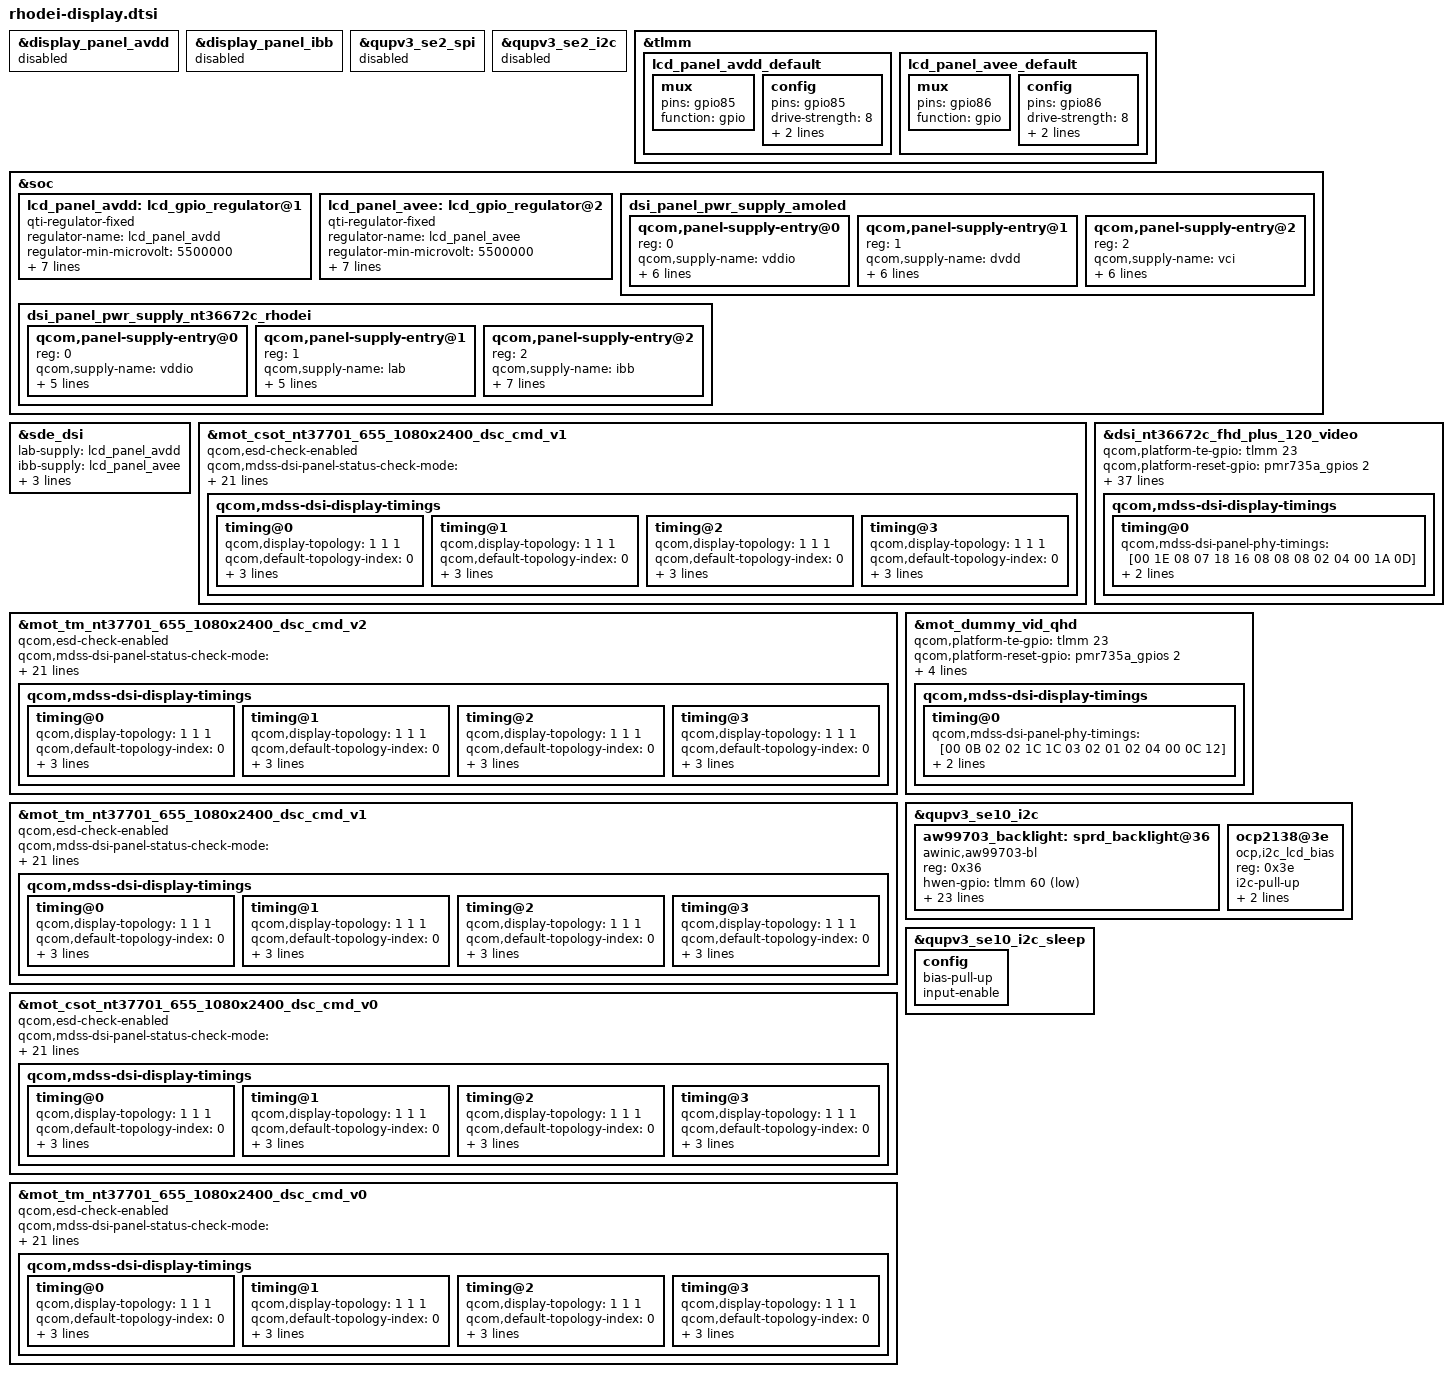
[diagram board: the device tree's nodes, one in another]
#include "dsi-panel-mot-csot-nt37701-655-1080x2400-dsc-cmd-common.dtsi"
#include "dsi-panel-mot-csot-nt37701-655-1080x2400-dsc-cmd-common-v1.dtsi"
#include "dsi-panel-mot-tianma-nt37701-655-1080x2400-dsc-cmd-common.dtsi"
#include "dsi-panel-mot-tianma-nt37701-655-1080x2400-dsc-cmd-common-v1.dtsi"
#include "dsi-panel-mot-tianma-nt37701-655-1080x2400-dsc-cmd-common-v2.dtsi"
#include "dsi-panel-mot-dummy-qhd-video.dtsi"
#include "dsi-panel-mot-tianma-nt36672c-645-1080x2400-video.dtsi"

&display_panel_avdd {
	/delete-property/ gpio;
	/delete-property/ pinctrl-0;
};

&display_panel_avdd {
	status = "disabled";
};

&display_panel_ibb {
	status = "disabled";
};

&qupv3_se2_spi {
	status = "disabled";
};

&qupv3_se2_i2c {
	status = "disabled";
};

&tlmm {
	lcd_panel_avdd_default: lcd_panel_avdd_default {
		mux {
			pins = "gpio85";
			function = "gpio";
		};

		config {
			pins = "gpio85";
			drive-strength = <8>;
			bias-disable = <0>;
			output-high;
		};
	};

	lcd_panel_avee_default: lcd_panel_avee_default {
		mux {
			pins = "gpio86";
			function = "gpio";
		};

		config {
			pins = "gpio86";
			drive-strength = <8>;
			bias-disable = <0>;
			output-high;
		};
	};
};

&soc {
	lcd_panel_avdd: lcd_gpio_regulator@1 {
		compatible = "qti-regulator-fixed";
		regulator-name = "lcd_panel_avdd";
		regulator-min-microvolt = <5500000>;
		regulator-max-microvolt = <5500000>;
		regulator-enable-ramp-delay = <233>;
		gpio = <&tlmm 85 0>;
		enable-active-high;
		regulator-boot-on;
		proxy-supply = <&lcd_panel_avdd>;
		pinctrl-names = "default";
		pinctrl-0 = <&lcd_panel_avdd_default>;
	};

	lcd_panel_avee: lcd_gpio_regulator@2 {
		compatible = "qti-regulator-fixed";
		regulator-name = "lcd_panel_avee";
		regulator-min-microvolt = <5500000>;
		regulator-max-microvolt = <5500000>;
		regulator-enable-ramp-delay = <233>;
		gpio = <&tlmm 86 0>;
		enable-active-high;
		regulator-boot-on;
		proxy-supply = <&lcd_panel_avee>;
		pinctrl-names = "default";
		pinctrl-0 = <&lcd_panel_avee_default>;
	};

	dsi_panel_pwr_supply_amoled: dsi_panel_pwr_supply_amoled {
		#address-cells = <1>;
		#size-cells = <0>;

		qcom,panel-supply-entry@0 {
			reg = <0>;
			qcom,supply-name = "vddio";
			qcom,supply-min-voltage = <1800000>;
			qcom,supply-max-voltage = <1800000>;
			qcom,supply-enable-load = <60700>;
			qcom,supply-disable-load = <80>;
		        qcom,supply-post-on-sleep = <2>;
			qcom,supply-post-off-sleep = <0>;
		};

		qcom,panel-supply-entry@1 {
			reg = <1>;
			qcom,supply-name = "dvdd";
			qcom,supply-min-voltage = <1250000>;
			qcom,supply-max-voltage = <1250000>;
			qcom,supply-enable-load = <60700>;
			qcom,supply-disable-load = <10>;
		        qcom,supply-post-on-sleep = <2>;
		        qcom,supply-post-off-sleep = <2>;
		};

		qcom,panel-supply-entry@2 {
			reg = <2>;
			qcom,supply-name = "vci";
			qcom,supply-min-voltage = <3000000>;
			qcom,supply-max-voltage = <3000000>;
			qcom,supply-enable-load = <30000>;
			qcom,supply-disable-load = <0>;
			qcom,supply-post-on-sleep = <0>;
			qcom,supply-post-off-sleep = <2>;
		};
	};

	dsi_panel_pwr_supply_nt36672c_rhodei: dsi_panel_pwr_supply_nt36672c_rhodei{
		#address-cells = <1>;
		#size-cells = <0>;

		qcom,panel-supply-entry@0 {
			reg = <0>;
			qcom,supply-name = "vddio";
			qcom,supply-min-voltage = <1800000>;
			qcom,supply-max-voltage = <1904000>;
			qcom,supply-enable-load = <32000>;
			qcom,supply-disable-load = <80>;
			qcom,supply-pre-off-sleep = <150>;
		};

		qcom,panel-supply-entry@1 {
			reg = <1>;
			qcom,supply-name = "lab";
			qcom,supply-min-voltage = <5500000>;
			qcom,supply-max-voltage = <5500000>;
			qcom,supply-enable-load = <100000>;
			qcom,supply-disable-load = <100>;
			qcom,supply-pre-on-sleep = <3>;
		};

		qcom,panel-supply-entry@2 {
			reg = <2>;
			qcom,supply-name = "ibb";
			qcom,supply-min-voltage = <5500000>;
			qcom,supply-max-voltage = <5500000>;
			qcom,supply-enable-load = <100000>;
			qcom,supply-disable-load = <100>;
			qcom,supply-pre-off-sleep = <3>;
			qcom,supply-post-on-sleep = <3>;
			qcom,supply-post-off-sleep = <5>;
		};

	};
};

&sde_dsi {
	/delete-property/ lab-supply;
	/delete-property/ ibb-supply;
	/delete-property/ vddio-supply;
	/delete-property/ qcom,dsi-default-panel;
	/delete-property/ avdd-supply;

	lab-supply = <&lcd_panel_avdd>;
	ibb-supply = <&lcd_panel_avee>;
	vddio-supply = <&L13A>;

	qcom,dsi-default-panel = <&dsi_nt36672c_fhd_plus_120_video>;
};

&mot_csot_nt37701_655_1080x2400_dsc_cmd_v1 {
	qcom,esd-check-enabled;
	qcom,mdss-dsi-panel-status-check-mode = "te_chk_reg_rd";
	qcom,mdss-dsi-panel-status-command = [06 01 00 01 00 00 01 0a];
	qcom,mdss-dsi-panel-status-command-state = "dsi_lp_mode";
	qcom,mdss-dsi-panel-status-value = <0x9c>;
	qcom,mdss-dsi-panel-status-read-length = <1>;

	qcom,panel-supply-entries = <&dsi_panel_pwr_supply_amoled>;
	qcom,mdss-dsi-no-panel-on-read-support;
	qcom,mdss-dsi-bl-pmic-control-type = "bl_ctrl_dcs";
	qcom,mdss-dsi-bl-min-level = <9>;
	qcom,mdss-dsi-bl-max-level = <3514>;
	qcom,mdss-dsi-bl-default-level = <1757>;
	qcom,mdss-brightness-max-level = <3514>;
	qcom,platform-te-gpio = <&tlmm 23 0>;
	qcom,platform-reset-gpio = <&pmr735a_gpios 2 0>;
	qcom,bl-dsc-cmd-state = "dsi_hs_mode";

	/*qcom,mdss-dsi-panel-hdr-enabled;
	qcom,mdss-dsi-panel-hdr-color-primaries = <14950 15750 34000
	        16000 13000 35500 7000 2500>;
	qcom,mdss-dsi-panel-peak-brightness = <5000000>;
	qcom,mdss-dsi-panel-blackness-level = <100>;*/

	qcom,dsi-select-clocks = "mux_byte_clk0", "mux_pixel_clk0";

	qcom,mdss-dsi-display-timings {
		timing@0 {
			//qcom,mdss-dsi-panel-clockrate = <320000000>;
			qcom,display-topology = <1 1 1>;
			qcom,default-topology-index = <0>;
			qcom,mdss-dsi-panel-phy-drive-strength = <255>;
			qcom,mdss-dsi-panel-phy-timings = [00 0D 03 03 10 1D 04
							03 02 02 04 00 0C 08];
		};
		timing@1 {
			//qcom,mdss-dsi-panel-clockrate = <400000000>;
			qcom,display-topology = <1 1 1>;
			qcom,default-topology-index = <0>;
			qcom,mdss-dsi-panel-phy-drive-strength = <255>;
			qcom,mdss-dsi-panel-phy-timings = [00 10 03 03 11 1E 04
							04 03 02 04 00 0E 08];
		};
		timing@2 {
			//qcom,mdss-dsi-panel-clockrate = <601000000>;
			qcom,display-topology = <1 1 1>;
			qcom,default-topology-index = <0>;
			qcom,mdss-dsi-panel-phy-drive-strength = <255>;
			qcom,mdss-dsi-panel-phy-timings = [00 16 05 05 14 1F 06
							06 06 02 04 00 13 0A];
		};
		timing@3 {
			//qcom,mdss-dsi-panel-clockrate = <801000000>;
			qcom,display-topology = <1 1 1>;
			qcom,default-topology-index = <0>;
			qcom,mdss-dsi-panel-phy-drive-strength = <255>;
			qcom,mdss-dsi-panel-phy-timings = [00 1C 07 07 17 15 07
							07 08 02 04 00 18 0C];
		};
		/*timing@4 {
			//qcom,mdss-dsi-panel-clockrate = <961000000>;
			qcom,display-topology = <1 1 1>;
			qcom,default-topology-index = <0>;
			qcom,mdss-dsi-panel-phy-drive-strength = <255>;
			qcom,mdss-dsi-panel-phy-timings = [00 21 08 08 19 17 08
							08 09 02 04 00 1C 0D];
		};*/
	};
};

&mot_tm_nt37701_655_1080x2400_dsc_cmd_v2 {
	qcom,esd-check-enabled;
	qcom,mdss-dsi-panel-status-check-mode = "te_chk_reg_rd";
	qcom,mdss-dsi-panel-status-command = [06 01 00 01 00 00 01 0a];
	qcom,mdss-dsi-panel-status-command-state = "dsi_lp_mode";
	qcom,mdss-dsi-panel-status-value = <0x9c>;
	qcom,mdss-dsi-panel-status-read-length = <1>;

	qcom,panel-supply-entries = <&dsi_panel_pwr_supply_amoled>;
	qcom,mdss-dsi-no-panel-on-read-support;
	qcom,mdss-dsi-bl-pmic-control-type = "bl_ctrl_dcs";
	qcom,mdss-dsi-bl-min-level = <9>;
	qcom,mdss-dsi-bl-max-level = <3514>;
	qcom,mdss-dsi-bl-default-level = <1757>;
	qcom,mdss-brightness-max-level = <3514>;
	qcom,platform-te-gpio = <&tlmm 23 0>;
	qcom,platform-reset-gpio = <&pmr735a_gpios 2 0>;
	qcom,bl-dsc-cmd-state = "dsi_hs_mode";

	/*qcom,mdss-dsi-panel-hdr-enabled;
	qcom,mdss-dsi-panel-hdr-color-primaries = <14950 15750 34000
	        16000 13000 35500 7000 2500>;
	qcom,mdss-dsi-panel-peak-brightness = <5000000>;
	qcom,mdss-dsi-panel-blackness-level = <100>;*/

	qcom,dsi-select-clocks = "mux_byte_clk0", "mux_pixel_clk0";

	qcom,mdss-dsi-display-timings {
		timing@0 {
			//qcom,mdss-dsi-panel-clockrate = <320000000>;
			qcom,display-topology = <1 1 1>;
			qcom,default-topology-index = <0>;
			qcom,mdss-dsi-panel-phy-drive-strength = <255>;
			qcom,mdss-dsi-panel-phy-timings = [00 0D 03 03 10 1D 04
							03 02 02 04 00 0C 08];
		};
		timing@1 {
			//qcom,mdss-dsi-panel-clockrate = <400000000>;
			qcom,display-topology = <1 1 1>;
			qcom,default-topology-index = <0>;
			qcom,mdss-dsi-panel-phy-drive-strength = <255>;
			qcom,mdss-dsi-panel-phy-timings = [00 10 03 03 11 1E 04
							04 03 02 04 00 0E 08];
		};
		timing@2 {
			//qcom,mdss-dsi-panel-clockrate = <601000000>;
			qcom,display-topology = <1 1 1>;
			qcom,default-topology-index = <0>;
			qcom,mdss-dsi-panel-phy-drive-strength = <255>;
			qcom,mdss-dsi-panel-phy-timings = [00 16 05 05 14 1F 06
							06 06 02 04 00 13 0A];
		};
		timing@3 {
			//qcom,mdss-dsi-panel-clockrate = <801000000>;
			qcom,display-topology = <1 1 1>;
			qcom,default-topology-index = <0>;
			qcom,mdss-dsi-panel-phy-drive-strength = <255>;
			qcom,mdss-dsi-panel-phy-timings = [00 1C 07 07 17 15 07
							07 08 02 04 00 18 0C];
		};
		/*timing@4 {
			//qcom,mdss-dsi-panel-clockrate = <961000000>;
			qcom,display-topology = <1 1 1>;
			qcom,default-topology-index = <0>;
			qcom,mdss-dsi-panel-phy-drive-strength = <255>;
			qcom,mdss-dsi-panel-phy-timings = [00 21 08 08 19 17 08
							08 09 02 04 00 1C 0D];
		};*/
	};
};

&mot_tm_nt37701_655_1080x2400_dsc_cmd_v1 {
	qcom,esd-check-enabled;
	qcom,mdss-dsi-panel-status-check-mode = "te_chk_reg_rd";
	qcom,mdss-dsi-panel-status-command = [06 01 00 01 00 00 01 0a];
	qcom,mdss-dsi-panel-status-command-state = "dsi_lp_mode";
	qcom,mdss-dsi-panel-status-value = <0x9c>;
	qcom,mdss-dsi-panel-status-read-length = <1>;

	qcom,panel-supply-entries = <&dsi_panel_pwr_supply_amoled>;
	qcom,mdss-dsi-no-panel-on-read-support;
	qcom,mdss-dsi-bl-pmic-control-type = "bl_ctrl_dcs";
	qcom,mdss-dsi-bl-min-level = <9>;
	qcom,mdss-dsi-bl-max-level = <3514>;
	qcom,mdss-dsi-bl-default-level = <1757>;
	qcom,mdss-brightness-max-level = <3514>;
	qcom,platform-te-gpio = <&tlmm 23 0>;
	qcom,platform-reset-gpio = <&pmr735a_gpios 2 0>;
	qcom,bl-dsc-cmd-state = "dsi_hs_mode";

	/*qcom,mdss-dsi-panel-hdr-enabled;
	qcom,mdss-dsi-panel-hdr-color-primaries = <14950 15750 34000
	        16000 13000 35500 7000 2500>;
	qcom,mdss-dsi-panel-peak-brightness = <5000000>;
	qcom,mdss-dsi-panel-blackness-level = <100>;*/

	qcom,dsi-select-clocks = "mux_byte_clk0", "mux_pixel_clk0";

	qcom,mdss-dsi-display-timings {
		timing@0 {
			//qcom,mdss-dsi-panel-clockrate = <320000000>;
			qcom,display-topology = <1 1 1>;
			qcom,default-topology-index = <0>;
			qcom,mdss-dsi-panel-phy-drive-strength = <255>;
			qcom,mdss-dsi-panel-phy-timings = [00 0D 03 03 10 1D 04
							03 02 02 04 00 0C 08];
		};
		timing@1 {
			//qcom,mdss-dsi-panel-clockrate = <400000000>;
			qcom,display-topology = <1 1 1>;
			qcom,default-topology-index = <0>;
			qcom,mdss-dsi-panel-phy-drive-strength = <255>;
			qcom,mdss-dsi-panel-phy-timings = [00 10 03 03 11 1E 04
							04 03 02 04 00 0E 08];
		};
		timing@2 {
			//qcom,mdss-dsi-panel-clockrate = <601000000>;
			qcom,display-topology = <1 1 1>;
			qcom,default-topology-index = <0>;
			vqcom,mdss-dsi-panel-phy-drive-strength = <255>;
			qcom,mdss-dsi-panel-phy-timings = [00 16 05 05 14 1F 06
							06 06 02 04 00 13 0A];
		};
		timing@3 {
			//qcom,mdss-dsi-panel-clockrate = <801000000>;
			qcom,display-topology = <1 1 1>;
			qcom,default-topology-index = <0>;
			qcom,mdss-dsi-panel-phy-drive-strength = <255>;
			qcom,mdss-dsi-panel-phy-timings = [00 1C 07 07 17 15 07
							07 08 02 04 00 18 0C];
		};
		/*timing@4 {
			//qcom,mdss-dsi-panel-clockrate = <961000000>;
			qcom,display-topology = <1 1 1>;
			qcom,default-topology-index = <0>;
			qcom,mdss-dsi-panel-phy-drive-strength = <255>;
			qcom,mdss-dsi-panel-phy-timings = [00 21 08 08 19 17 08
							08 09 02 04 00 1C 0D];
		};*/
	};
};

&mot_csot_nt37701_655_1080x2400_dsc_cmd_v0 {
	qcom,esd-check-enabled;
	qcom,mdss-dsi-panel-status-check-mode = "te_chk_reg_rd";
	qcom,mdss-dsi-panel-status-command = [06 01 00 01 00 00 01 0a];
	qcom,mdss-dsi-panel-status-command-state = "dsi_lp_mode";
	qcom,mdss-dsi-panel-status-value = <0x9c>;
	qcom,mdss-dsi-panel-status-read-length = <1>;

	qcom,panel-supply-entries = <&dsi_panel_pwr_supply_amoled>;
	qcom,mdss-dsi-no-panel-on-read-support;
	qcom,mdss-dsi-bl-pmic-control-type = "bl_ctrl_dcs";
	qcom,mdss-dsi-bl-min-level = <9>;
	qcom,mdss-dsi-bl-max-level = <3514>;
	qcom,mdss-dsi-bl-default-level = <1757>;
	qcom,mdss-brightness-max-level = <3514>;
	qcom,platform-te-gpio = <&tlmm 23 0>;
	qcom,platform-reset-gpio = <&pmr735a_gpios 2 0>;
	qcom,bl-dsc-cmd-state = "dsi_hs_mode";

	/*qcom,mdss-dsi-panel-hdr-enabled;
	qcom,mdss-dsi-panel-hdr-color-primaries = <14950 15750 34000
	        16000 13000 35500 7000 2500>;
	qcom,mdss-dsi-panel-peak-brightness = <5000000>;
	qcom,mdss-dsi-panel-blackness-level = <100>;*/

	qcom,dsi-select-clocks = "mux_byte_clk0", "mux_pixel_clk0";

	qcom,mdss-dsi-display-timings {
		timing@0 {
			//qcom,mdss-dsi-panel-clockrate = <320000000>;
			qcom,display-topology = <1 1 1>;
			qcom,default-topology-index = <0>;
			qcom,mdss-dsi-panel-phy-drive-strength = <255>;
			qcom,mdss-dsi-panel-phy-timings = [00 0D 03 03 10 1D 04
							03 02 02 04 00 0C 08];
		};
		timing@1 {
			//qcom,mdss-dsi-panel-clockrate = <400000000>;
			qcom,display-topology = <1 1 1>;
			qcom,default-topology-index = <0>;
			qcom,mdss-dsi-panel-phy-drive-strength = <255>;
			qcom,mdss-dsi-panel-phy-timings = [00 10 03 03 11 1E 04
							04 03 02 04 00 0E 08];
		};
		timing@2 {
			//qcom,mdss-dsi-panel-clockrate = <601000000>;
			qcom,display-topology = <1 1 1>;
			qcom,default-topology-index = <0>;
			qcom,mdss-dsi-panel-phy-drive-strength = <255>;
			qcom,mdss-dsi-panel-phy-timings = [00 16 05 05 14 1F 06
							06 06 02 04 00 13 0A];
		};
		timing@3 {
			//qcom,mdss-dsi-panel-clockrate = <801000000>;
			qcom,display-topology = <1 1 1>;
			qcom,default-topology-index = <0>;
			qcom,mdss-dsi-panel-phy-drive-strength = <255>;
			qcom,mdss-dsi-panel-phy-timings = [00 1C 07 07 17 15 07
							07 08 02 04 00 18 0C];
		};
		/*timing@4 {
			//qcom,mdss-dsi-panel-clockrate = <961000000>;
			qcom,display-topology = <1 1 1>;
			qcom,default-topology-index = <0>;
			qcom,mdss-dsi-panel-phy-drive-strength = <255>;
			qcom,mdss-dsi-panel-phy-timings = [00 21 08 08 19 17 08
							08 09 02 04 00 1C 0D];
		};*/
	};
};

&mot_tm_nt37701_655_1080x2400_dsc_cmd_v0 {
	qcom,esd-check-enabled;
	qcom,mdss-dsi-panel-status-check-mode = "te_chk_reg_rd";
	qcom,mdss-dsi-panel-status-command = [06 01 00 01 00 00 01 0a];
	qcom,mdss-dsi-panel-status-command-state = "dsi_lp_mode";
	qcom,mdss-dsi-panel-status-value = <0x9c>;
	qcom,mdss-dsi-panel-status-read-length = <1>;

	qcom,panel-supply-entries = <&dsi_panel_pwr_supply_amoled>;
	qcom,mdss-dsi-no-panel-on-read-support;
	qcom,mdss-dsi-bl-pmic-control-type = "bl_ctrl_dcs";
	qcom,mdss-dsi-bl-min-level = <9>;
	qcom,mdss-dsi-bl-max-level = <3514>;
	qcom,mdss-dsi-bl-default-level = <1757>;
	qcom,mdss-brightness-max-level = <3514>;
	qcom,platform-te-gpio = <&tlmm 23 0>;
	qcom,platform-reset-gpio = <&pmr735a_gpios 2 0>;
	qcom,bl-dsc-cmd-state = "dsi_hs_mode";

	/*qcom,mdss-dsi-panel-hdr-enabled;
	qcom,mdss-dsi-panel-hdr-color-primaries = <14950 15750 34000
	        16000 13000 35500 7000 2500>;
	qcom,mdss-dsi-panel-peak-brightness = <5000000>;
	qcom,mdss-dsi-panel-blackness-level = <100>;*/

	qcom,dsi-select-clocks = "mux_byte_clk0", "mux_pixel_clk0";

	qcom,mdss-dsi-display-timings {
		timing@0 {
			//qcom,mdss-dsi-panel-clockrate = <320000000>;
			qcom,display-topology = <1 1 1>;
			qcom,default-topology-index = <0>;
			qcom,mdss-dsi-panel-phy-drive-strength = <255>;
			qcom,mdss-dsi-panel-phy-timings = [00 0D 03 03 10 1D 04
							03 02 02 04 00 0C 08];
		};
		timing@1 {
			//qcom,mdss-dsi-panel-clockrate = <400000000>;
			qcom,display-topology = <1 1 1>;
			qcom,default-topology-index = <0>;
			qcom,mdss-dsi-panel-phy-drive-strength = <255>;
			qcom,mdss-dsi-panel-phy-timings = [00 10 03 03 11 1E 04
							04 03 02 04 00 0E 08];
		};
		timing@2 {
			//qcom,mdss-dsi-panel-clockrate = <601000000>;
			qcom,display-topology = <1 1 1>;
			qcom,default-topology-index = <0>;
			qcom,mdss-dsi-panel-phy-drive-strength = <255>;
			qcom,mdss-dsi-panel-phy-timings = [00 16 05 05 14 1F 06
							06 06 02 04 00 13 0A];
		};
		timing@3 {
			//qcom,mdss-dsi-panel-clockrate = <801000000>;
			qcom,display-topology = <1 1 1>;
			qcom,default-topology-index = <0>;
			qcom,mdss-dsi-panel-phy-drive-strength = <255>;
			qcom,mdss-dsi-panel-phy-timings = [00 1C 07 07 17 15 07
							07 08 02 04 00 18 0C];
		};
		/*timing@4 {
			//qcom,mdss-dsi-panel-clockrate = <961000000>;
			qcom,display-topology = <1 1 1>;
			qcom,default-topology-index = <0>;
			qcom,mdss-dsi-panel-phy-drive-strength = <255>;
			qcom,mdss-dsi-panel-phy-timings = [00 21 08 08 19 17 08
							08 09 02 04 00 1C 0D];
		};*/
	};
};

&dsi_nt36672c_fhd_plus_120_video {
	qcom,platform-te-gpio = <&tlmm 23 0>;
	qcom,platform-reset-gpio = <&pmr735a_gpios 2 0>;

	qcom,panel-supply-entries = <&dsi_panel_pwr_supply_nt36672c_rhodei>;
	qcom,mdss-dsi-bl-pmic-control-type = "bl_ctrl_i2c";
	qcom,mdss-dsi-bl-min-level = <8>;
	qcom,mdss-dsi-bl-max-level = <2047>;
	qcom,mdss-dsi-bl-default-level = <1024>;
	qcom,mdss-brightness-max-level = <2047>;
	qcom,mdss-dsi-no-panel-on-read-support;

	qcom,esd-check-enabled;
	qcom,mdss-dsi-panel-status-check-mode = "reg_read";
	qcom,mdss-dsi-panel-status-command = [06 01 00 01 00 00 01 0a];
	qcom,mdss-dsi-panel-status-command-state = "dsi_lp_mode";
	qcom,mdss-dsi-panel-status-value = <0x9c>;
	qcom,mdss-dsi-panel-on-check-value = <0x9c>;
	qcom,mdss-dsi-panel-status-read-length = <1>;

	qcom,tp_state_check_enable;

	qcom,dsi-supported-dfps-list = <120 90 60>;
	qcom,mdss-dsi-pan-enable-dynamic-fps;
	qcom,mdss-dsi-pan-fps-update = "dfps_immediate_porch_mode_vfp";

	qcom,mdss-dsi-hbm-on-command = [15 01 00 00 00 00 02 51 FF];
	qcom,mdss-dsi-hbm-on-command-state =  "dsi_lp_mode";
	qcom,mdss-dsi-hbm-off-command = [15 01 00 00 00 00 02 51 CC];
	qcom,mdss-dsi-hbm-off-command-state =  "dsi_lp_mode";
	qcom,mdss-dsi-hbm-type = "lcd-dcs-wled";

	qcom,dsi-select-clocks = "mux_byte_clk0", "mux_pixel_clk0";
	qcom,mdss-dsi-t-clk-post = <0x0D>;
	qcom,mdss-dsi-t-clk-pre = <0x1A>;
	qcom,mdss-dsi-display-timings {
		timing@0 {
			qcom,mdss-dsi-panel-phy-timings = [00 1E 08 07 18 16 08 08 08 02 04 00 1A 0D];
			qcom,display-topology = <1 1 1>;
			qcom,default-topology-index = <0>;
		};
	};
};

&mot_dummy_vid_qhd {
	qcom,platform-te-gpio = <&tlmm 23 0>;
	qcom,platform-reset-gpio = <&pmr735a_gpios 2 0>;

	qcom,mdss-dsi-bl-pmic-control-type = "bl_ctrl_dummy";

	qcom,dsi-select-clocks = "mux_byte_clk0", "mux_pixel_clk0";

	qcom,mdss-dsi-display-timings {
		timing@0 {
			qcom,mdss-dsi-panel-phy-timings = [00 0B 02 02 1C 1C 03
							02 01 02 04 00 0C 12];
			qcom,display-topology = <1 0 1>;
			qcom,default-topology-index = <0>;
		};
	};
};

&qupv3_se10_i2c {
	status = "ok";

	aw99703_backlight: sprd_backlight@36{
		compatible = "awinic,aw99703-bl","sm-sm5350";
		reg = <0x36>;
		hwen-gpio = <&tlmm 60 1>;
                aw99703,bl-map = <3>; /* brightness map level 1:256,2:1024,3:2048 */
                aw99703,using-lsb;
                aw99703,ovp-level = <2>; /* 0:17.5V, 1:24V, 2:31V, 3:38V, 4:41.5V */
                aw99703,ocp-level = <1>; /* 0:0.9A, 1:1.8A, 2:2.7A, 3:3.4A */
                aw99703,switch-freq = <1>; /* 1000kHz(default) */
                aw99703,auto-freq-high = <0x10>;
                aw99703,auto-freq-low = <0x05>;
                aw99703,bl-fscal-led = <0x17>; /* 24.8mA */
                aw99703,bl-channel = <3>;
                aw99703,turn-on-ramp = <0x00>; /* 512us */
                aw99703,turn-off-ramp = <0x04>; /* 8ms */
                aw99703,pwm-trans-dim = <0>; /* 2ms */
                aw99703,i2c-trans-dim = <1>; /* 128ms */
                aw99703,pwm-mode = <1>; /* 1 pwm enable,0 PWM disable */
                aw99703,map-type = <0>; /* 0 exponential, 4 linear */
                aw99703,work-mode = <1>; /* backlight */
		aw99703,default-brightness = <1810>;

		status = "okay";
		pwm-cfg = <0x0F>;
		boost-ctl = <0x03>;
		ctl-bank-en = <0x02>;
		full-scale-current = <0x17>;
		map-mode = <0>; /* 0 exponential, 1 linear */
		sm5350,default-brightness = <1810>;
	};

             ocp2138@3e {
                       compatible = "ocp,i2c_lcd_bias";
                       reg = <0x3e>;
                       i2c-pull-up;
                       ocp,lcd-bias-enn-gpio = <&tlmm 85 0>;
                       ocp,lcd-bias-enp-gpio = <&tlmm 86 0>;
        };
};

&qupv3_se10_i2c_sleep {
    config {
        /delete-property/ bias-disable;
        bias-pull-up;
        input-enable;
    };
};

